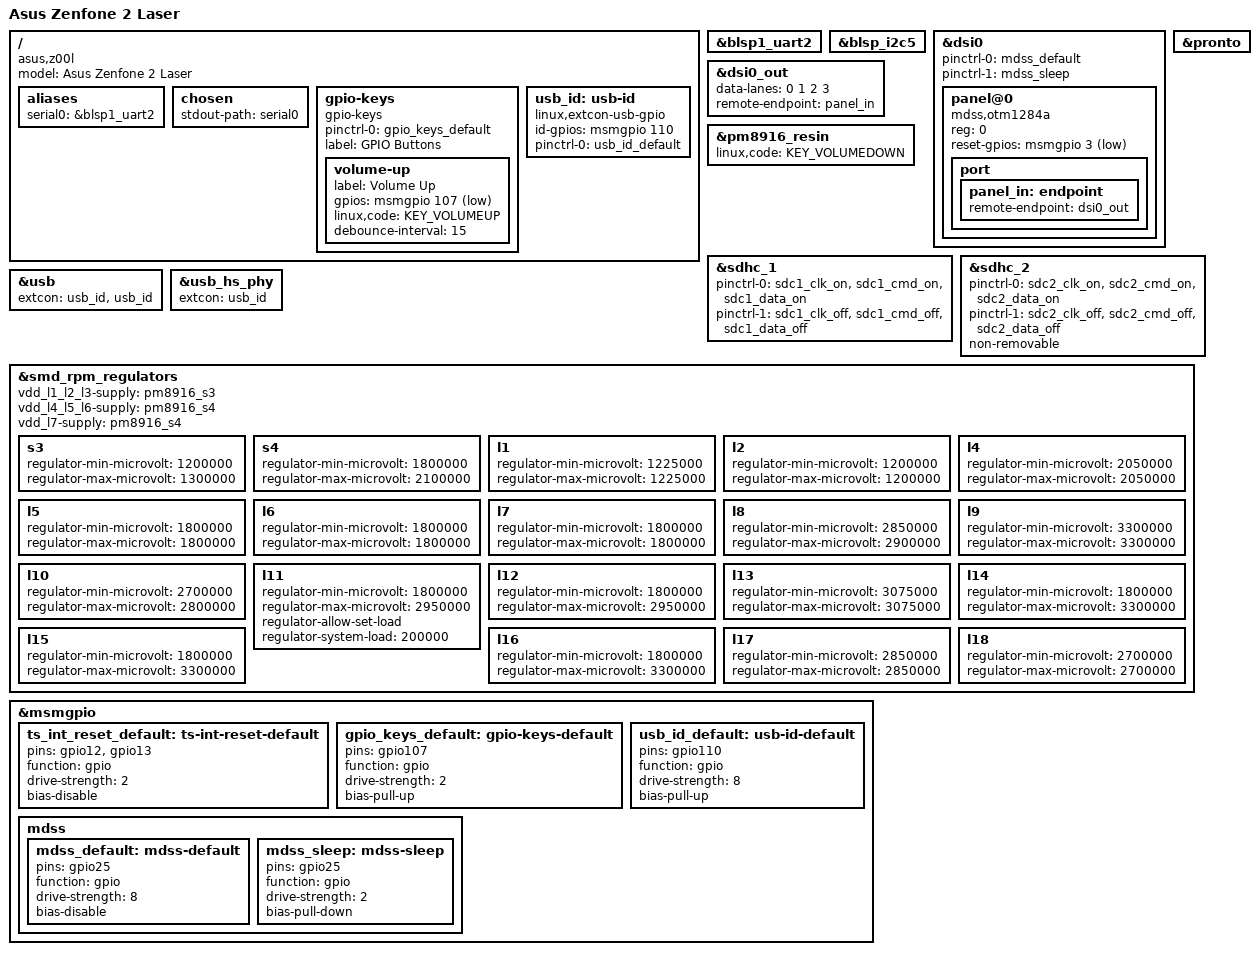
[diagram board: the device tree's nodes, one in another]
// SPDX-License-Identifier: GPL-2.0-only

/dts-v1/;

#include "msm8916-pm8916.dtsi"
#include "msm8916-no-psci.dtsi"
#include <dt-bindings/gpio/gpio.h>
#include <dt-bindings/input/input.h>
#include <dt-bindings/interrupt-controller/irq.h>
#include <dt-bindings/pinctrl/qcom,pmic-mpp.h>


/ {
 	model = "Asus Zenfone 2 Laser";
 	compatible = "asus,z00l", "qcom,msm8916";

	aliases {
		serial0 = &blsp1_uart2;
	};

	chosen {
		stdout-path = "serial0";
	};
	
	gpio-keys {
		compatible = "gpio-keys";

		pinctrl-names = "default";
		pinctrl-0 = <&gpio_keys_default>;

		label = "GPIO Buttons";

		volume-up {
			label = "Volume Up";
			gpios = <&msmgpio 107 GPIO_ACTIVE_LOW>;
			linux,code = <KEY_VOLUMEUP>;
			debounce-interval = <15>;
		};
	};

	usb_id: usb-id {
		compatible = "linux,extcon-usb-gpio";
		id-gpios = <&msmgpio 110 GPIO_ACTIVE_HIGH>;
		pinctrl-names = "default";
		pinctrl-0 = <&usb_id_default>;
	};
};

&blsp1_uart2 {
	status = "okay";
};


&blsp_i2c5 {
        status = "okay";
/*
	focaltech@38 {
		compatible = "focaltech,5x06";
		reg = <0x38>;
		interrupt-parent = <&msmgpio>;
		interrupts = <13 IRQ_TYPE_EDGE_FALLING>;
		
		reset-gpio = <&msmgpio 12 GPIO_ACTIVE_HIGH>;

		vdd-supply = <&pm8916_l11>;
		vcc_i2c-supply = <&pm8916_l6>;
	
		linux,keycodes = <KEY_BACK KEY_HOMEPAGE KEY_APPSELECT>;
	
	};
*/

/*
	rmi4@20 {
		compatible = "syna,rmi4-2c";
		reg = <0x20>;
		#address-cells = <1>;
		#size-cells = <0>;

		interrupt-parent = <&msmgpio>;
		interrupts = <13 IRQ_TYPE_EDGE_FALLING>;

		reset-gpio = <&msmgpio 12 GPIO_ACTIVE_LOW>;
	
		pinctrl-names = "default";
		pinctrl-0 = <&ts_int_reset_default>;
		syna,startup-delay-ms = <10>;

		rmi4-f01@1 {
			reg = <0x1>;
			syna,nosleep-mode = <1>; // Allow sleeping
		};

		rmi4-f12@12 {
			reg = <0x12>;
			syna,sensor-type = <1>; // Touchscreen
		};
	};
*/
};


&dsi0 {
	pinctrl-names = "default", "sleep";
        pinctrl-0 = <&mdss_default>;
        pinctrl-1 = <&mdss_sleep>;
        panel@0 {
                compatible = "mdss,otm1284a";
                reg = <0>;

		reset-gpios = <&msmgpio 3 GPIO_ACTIVE_LOW>;

		port {
                        panel_in: endpoint {
                                remote-endpoint = <&dsi0_out>;
                        };
                };
        };
};

&dsi0_out {
        data-lanes = <0 1 2 3>;
        remote-endpoint = <&panel_in>;
};

&pm8916_resin {
	status = "okay";
	linux,code = <KEY_VOLUMEDOWN>;
};

&pronto {
	status = "okay";
};

&sdhc_1 {
	status = "okay";

	pinctrl-names = "default", "sleep";
	pinctrl-0 = <&sdc1_clk_on &sdc1_cmd_on &sdc1_data_on>;
	pinctrl-1 = <&sdc1_clk_off &sdc1_cmd_off &sdc1_data_off>;
};


&sdhc_2 {
	status = "okay";

	pinctrl-names = "default", "sleep";
	pinctrl-0 = <&sdc2_clk_on &sdc2_cmd_on &sdc2_data_on>; 
	pinctrl-1 = <&sdc2_clk_off &sdc2_cmd_off &sdc2_data_off>;

	// FIXME: Pick one! See below and compare with downstream...
	//cd-gpios = <&msmgpio 38 GPIO_ACTIVE_LOW>;
	non-removable;
};

&usb {
	status = "okay";
	extcon = <&usb_id>, <&usb_id>;
};

&usb_hs_phy {
	extcon = <&usb_id>;
};

&smd_rpm_regulators {
	vdd_l1_l2_l3-supply = <&pm8916_s3>;
	vdd_l4_l5_l6-supply = <&pm8916_s4>;
	vdd_l7-supply = <&pm8916_s4>;

	s3 {
		regulator-min-microvolt = <1200000>;
		regulator-max-microvolt = <1300000>;
	};

	s4 {
		regulator-min-microvolt = <1800000>;
		regulator-max-microvolt = <2100000>;
	};

	l1 {
		regulator-min-microvolt = <1225000>;
		regulator-max-microvolt = <1225000>;
	};

	l2 {
		regulator-min-microvolt = <1200000>;
		regulator-max-microvolt = <1200000>;
	};

	l4 {
		regulator-min-microvolt = <2050000>;
		regulator-max-microvolt = <2050000>;
	};

	l5 {
		regulator-min-microvolt = <1800000>;
		regulator-max-microvolt = <1800000>;
	};

	l6 {
		regulator-min-microvolt = <1800000>;
		regulator-max-microvolt = <1800000>;
	};

	l7 {
		regulator-min-microvolt = <1800000>;
		regulator-max-microvolt = <1800000>;
	};

	l8 {
		regulator-min-microvolt = <2850000>;
		regulator-max-microvolt = <2900000>;
	};

	l9 {
		regulator-min-microvolt = <3300000>;
		regulator-max-microvolt = <3300000>;
	};

	l10 {
		regulator-min-microvolt = <2700000>;
		regulator-max-microvolt = <2800000>;
	};

	l11 {
		regulator-min-microvolt = <1800000>;
		regulator-max-microvolt = <2950000>;
		regulator-allow-set-load;
		regulator-system-load = <200000>;
	};

	l12 {
		regulator-min-microvolt = <1800000>;
		regulator-max-microvolt = <2950000>;
	};

	l13 {
		regulator-min-microvolt = <3075000>;
		regulator-max-microvolt = <3075000>;
	};

	l14 {
		regulator-min-microvolt = <1800000>;
		regulator-max-microvolt = <3300000>;
	};

	l15 {
		regulator-min-microvolt = <1800000>;
		regulator-max-microvolt = <3300000>;
	};

	l16 {
		regulator-min-microvolt = <1800000>;
		regulator-max-microvolt = <3300000>;
	};

	l17 {
		regulator-min-microvolt = <2850000>;
		regulator-max-microvolt = <2850000>;
	};

	l18 {
		regulator-min-microvolt = <2700000>;
		regulator-max-microvolt = <2700000>;
	};
};

&msmgpio {
       /* add pingrp for touchscreen */
       ts_int_reset_default: ts-int-reset-default {
		pins = "gpio12", "gpio13";
		function = "gpio";

		drive-strength = <2>;
		bias-disable;
	};

/*
	ts_int_active: ts_int_active {
	       label = "ts_int_active";
               pins = "gpio13";
	       function = "gpio";
	       num-grp-pins = <1>;

	       drive-strength = <16>;
               bias-pull-up;
       };
          
       ts_int_suspend: ts_int_suspend {
	       label = "ts_int_suspend";
	       pins = "gpio13";
	       function = "gpio";
	       num-grp-pins = <1>;
	       drive-strength = <2>;
               bias-pull-down;
       };

       ts_reset_active: ts_reset_active {
		label = "ts_reset_active";
                pins = "gpio12";
		function = "gpio";
                drive-strength = <16>;
                bias-pull-up;
        };
          
        ts_reset_suspend: ts_reset_suspend {
                label = "ts_reset_suspend";
		pins = "gpio12";
		function = "gpio";
		num-grp-pins = <1>;
		drive-strength = <2>;
                bias-pull-down;
        };
           
        ts_release: ts_release {
		label = "ts_release";
                pins = "gpio13", "gpio12";
		num-grp-pins = <2>;
		drive-strength = <2>;
                bias-pull-down;
        };
*/	
	gpio_keys_default: gpio-keys-default {
		pins = "gpio107";
		function = "gpio";

		drive-strength = <2>;
		bias-pull-up;
	};

	usb_id_default: usb-id-default {
		pins = "gpio110";
		function = "gpio";

		drive-strength = <8>;
		bias-pull-up;
	};

	mdss {
		mdss_default: mdss-default {
			pins = "gpio25";
			function = "gpio";

			drive-strength = <8>;
			bias-disable;
		};
		mdss_sleep: mdss-sleep {
			pins = "gpio25";
			function = "gpio";

			drive-strength = <2>;
			bias-pull-down;
		};
	};

};
